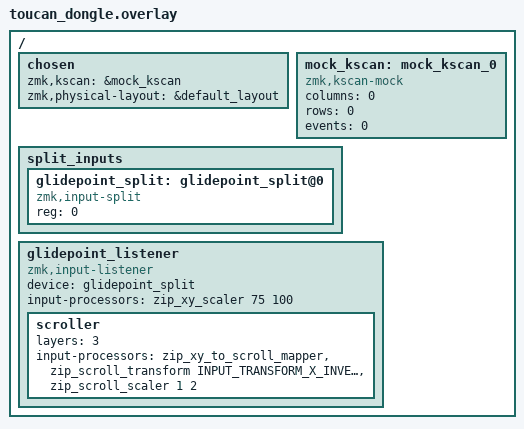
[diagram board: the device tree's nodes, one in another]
#include "../toucan/toucan_layout.dtsi"
#include <input/processors.dtsi>
#include <dt-bindings/zmk/input_transform.h>

/ {
    chosen {
        zmk,kscan = &mock_kscan;
        zmk,physical-layout = &default_layout;
    };

    mock_kscan: mock_kscan_0 {
        compatible = "zmk,kscan-mock";
        columns = <0>;
        rows = <0>;
        events = <0>;
    };

    split_inputs {
        #address-cells = <1>;
        #size-cells = <0>;

        glidepoint_split: glidepoint_split@0 {
            compatible = "zmk,input-split";
            reg = <0>;
        };
    };

    glidepoint_listener: glidepoint_listener {
        compatible = "zmk,input-listener";
        status = "okay";
        device = <&glidepoint_split>;
        input-processors = <&zip_xy_scaler 75 100>;
        scroller {
            layers = <3>;
            input-processors = <
                &zip_xy_to_scroll_mapper
                &zip_scroll_transform INPUT_TRANSFORM_X_INVERT
                &zip_scroll_scaler 1 2
            >;
        };
    };
};
